# AT91SAM9G20 register map
Vendor: Atmel; File version: 20130207
CPU: 
Registers are 32-bit, read-write, reset 0x0 unless marked. A register's access mark holds for its fields unless they carry their own. Offsets are from the block's base; [hi:lo] are bit positions; 'fields as' and 'values as' point back to an identical list.

## DBGU — Debug Unit
Base 0xFFFFF200; register names take the prefix DBGU_
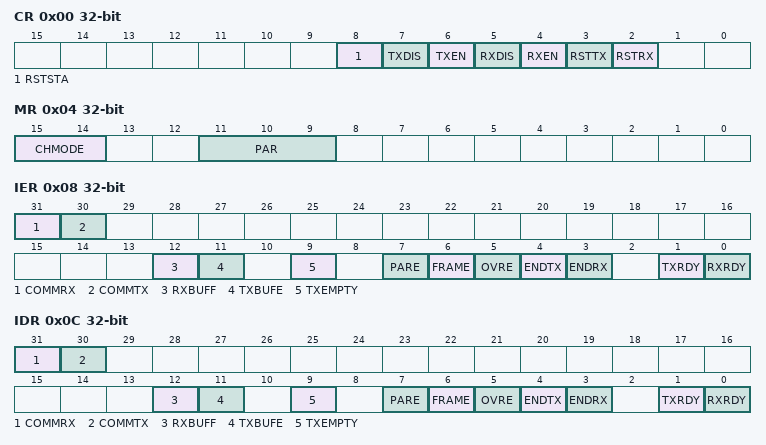
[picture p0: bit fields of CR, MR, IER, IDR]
0x00 CR wo reset not defined — Control Register
  [8] RSTSTA — Reset Status Bits
  [7] TXDIS — Transmitter Disable
  [6] TXEN — Transmitter Enable
  [5] RXDIS — Receiver Disable
  [4] RXEN — Receiver Enable
  [3] RSTTX — Reset Transmitter
  [2] RSTRX — Reset Receiver
0x04 MR — Mode Register
  [15:14] CHMODE — Channel Mode
    0=NORM (Normal Mode); 1=AUTO (Automatic Echo); 2=LOCLOOP (Local Loopback); 3=REMLOOP (Remote Loopback)
  [11:9] PAR — Parity Type
    0=EVEN (Even Parity); 1=ODD (Odd Parity); 2=SPACE (Space: Parity forced to 0); 3=MARK (Mark: Parity forced to 1); 4=NONE (No Parity)
0x08 IER wo reset not defined — Interrupt Enable Register
  [31] COMMRX — Enable COMMRX (from ARM) Interrupt
  [30] COMMTX — Enable COMMTX (from ARM) Interrupt
  [12] RXBUFF — Enable Buffer Full Interrupt
  [11] TXBUFE — Enable Buffer Empty Interrupt
  [9] TXEMPTY — Enable TXEMPTY Interrupt
  [7] PARE — Enable Parity Error Interrupt
  [6] FRAME — Enable Framing Error Interrupt
  [5] OVRE — Enable Overrun Error Interrupt
  [4] ENDTX — Enable End of Transmit Interrupt
  [3] ENDRX — Enable End of Receive Transfer Interrupt
  [1] TXRDY — Enable TXRDY Interrupt
  [0] RXRDY — Enable RXRDY Interrupt
0x0C IDR wo reset not defined — Interrupt Disable Register
  [31] COMMRX — Disable COMMRX (from ARM) Interrupt
  [30] COMMTX — Disable COMMTX (from ARM) Interrupt
  [12] RXBUFF — Disable Buffer Full Interrupt
  [11] TXBUFE — Disable Buffer Empty Interrupt
  [9] TXEMPTY — Disable TXEMPTY Interrupt
  [7] PARE — Disable Parity Error Interrupt
  [6] FRAME — Disable Framing Error Interrupt
  [5] OVRE — Disable Overrun Error Interrupt
  [4] ENDTX — Disable End of Transmit Interrupt
  [3] ENDRX — Disable End of Receive Transfer Interrupt
  [1] TXRDY — Disable TXRDY Interrupt
  [0] RXRDY — Disable RXRDY Interrupt
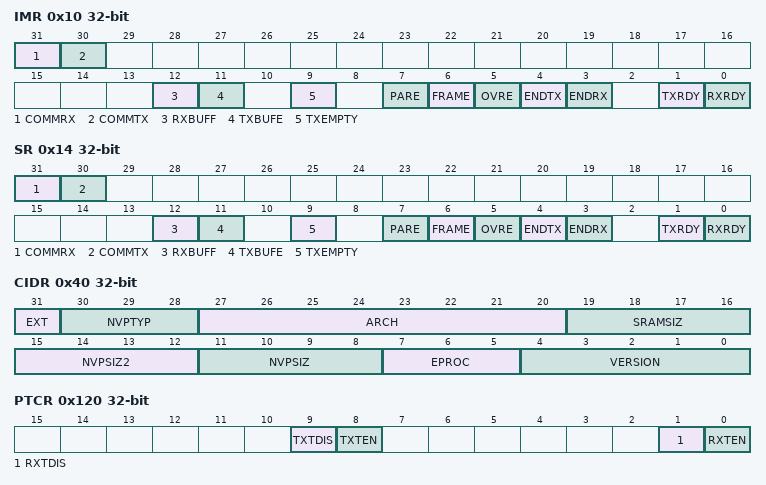
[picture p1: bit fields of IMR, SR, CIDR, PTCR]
0x10 IMR ro — Interrupt Mask Register
  [31] COMMRX — Mask COMMRX Interrupt
  [30] COMMTX — Mask COMMTX Interrupt
  [12] RXBUFF — Mask RXBUFF Interrupt
  [11] TXBUFE — Mask TXBUFE Interrupt
  [9] TXEMPTY — Mask TXEMPTY Interrupt
  [7] PARE — Mask Parity Error Interrupt
  [6] FRAME — Mask Framing Error Interrupt
  [5] OVRE — Mask Overrun Error Interrupt
  [4] ENDTX — Mask End of Transmit Interrupt
  [3] ENDRX — Mask End of Receive Transfer Interrupt
  [1] TXRDY — Disable TXRDY Interrupt
  [0] RXRDY — Mask RXRDY Interrupt
0x14 SR ro reset not defined — Status Register
  [31] COMMRX — Debug Communication Channel Read Status
  [30] COMMTX — Debug Communication Channel Write Status
  [12] RXBUFF — Receive Buffer Full
  [11] TXBUFE — Transmission Buffer Empty
  [9] TXEMPTY — Transmitter Empty
  [7] PARE — Parity Error
  [6] FRAME — Framing Error
  [5] OVRE — Overrun Error
  [4] ENDTX — End of Transmitter Transfer
  [3] ENDRX — End of Receiver Transfer
  [1] TXRDY — Transmitter Ready
  [0] RXRDY — Receiver Ready
0x18 RHR ro — Receive Holding Register
  [7:0] RXCHR — Received Character
0x1C THR wo reset not defined — Transmit Holding Register
  [7:0] TXCHR — Character to be Transmitted
0x20 BRGR — Baud Rate Generator Register
  [15:0] CD — Clock Divisor
    0=DISABLED (DBGU Disabled); 1=MCK
0x40 CIDR ro reset not defined — Chip ID Register
  [31] EXT — Extension Flag
  [30:28] NVPTYP — Nonvolatile Program Memory Type
    0=ROM; 1=ROMLESS (ROMless or on-chip Flash); 2=FLASH (Embedded Flash Memory); 3=ROM_FLASH (ROM and Embedded Flash MemoryNVPSIZ is ROM size NVPSIZ2 is Flash size); 4=SRAM (SRAM emulating ROM)
  [27:20] ARCH — Architecture Identifier
    25=AT91SAM9xx Series; 41=AT91SAM9XExx Series; 52=AT91x34 Series; 55=CAP7 (CAP7 Series); 57=CAP9 (CAP9 Series); 59=CAP11 (CAP11 Series); 64=AT91x40 Series; 66=AT91x42 Series; 85=AT91x55 Series; 96=AT91SAM7Axx Series; 97=AT91SAM7AQxx Series; 99=AT91x63 Series; 112=AT91SAM7Sxx Series; 113=AT91SAM7XCxx Series; 114=AT91SAM7SExx Series; 115=AT91SAM7Lxx Series; 117=AT91SAM7Xxx Series; 118=AT91SAM7SLxx Series; 128=ATSAM3UxC Series (100-pin version); 129=ATSAM3UxE Series (144-pin version); 131=ATSAM3AxC Series (100-pin version); 132=ATSAM3XxC Series (100-pin version); 133=ATSAM3XxE Series (144-pin version); 134=ATSAM3XxG Series (208/217-pin version); 136=ATSAM3SxA Series (48-pin version); 137=ATSAM3SxB Series (64-pin version); 138=ATSAM3SxC Series (100-pin version); 146=AT91x92 Series; 147=ATSAM3NxA Series (48-pin version); 148=ATSAM3NxB Series (64-pin version); 149=ATSAM3NxC Series (100-pin version); 152=ATSAM3SDxA Series (48-pin version); 153=ATSAM3SDxB Series (64-pin version); 154=ATSAM3SDxC Series (100-pin version); 240=AT75Cxx Series
  [19:16] SRAMSIZ — Internal SRAM Size
    1=1K (1K bytes); 2=2K (2K bytes); 3=6K (6K bytes); 4=112K (112K bytes); 5=4K (4K bytes); 6=80K (80K bytes); 7=160K (160K bytes); 8=8K (8K bytes); 9=16K (16K bytes); 10=32K (32K bytes); 11=64K (64K bytes); 12=128K (128K bytes); 13=256K (256K bytes); 14=96K (96K bytes); 15=512K (512K bytes)
  [15:12] NVPSIZ2
    0=NONE; 1=8K (8K bytes); 2=16K (16K bytes); 3=32K (32K bytes); 5=64K (64K bytes); 7=128K (128K bytes); 9=256K (256K bytes); 10=512K (512K bytes); 12=1024K (1024K bytes); 14=2048K (2048K bytes)
  [11:8] NVPSIZ — Nonvolatile Program Memory Size
    values as NVPSIZ2
  [7:5] EPROC — Embedded Processor
    1=ARM946ES; 2=ARM7TDMI; 3=CM3 (Cortex-M3); 4=ARM920T; 5=ARM926EJS; 6=CA5 (Cortex-A5)
  [4:0] VERSION — Version of the Device
0x44 EXID ro reset not defined — Chip ID Extension Register
  [31:0] EXID — Chip ID Extension
0x48 FNR — Force NTRST Register
  [0] FNTRST — Force NTRST
0x100 RPR — Receive Pointer Register
  [31:0] RXPTR
0x104 RCR — Receive Counter Register
  [15:0] RXCTR
0x108 TPR — Transmit Pointer Register
  [31:0] TXPTR — Transmit Counter Register
0x10C TCR — Transmit Counter Register
  [15:0] TXCTR
0x110 RNPR — Receive Next Pointer Register
  [31:0] RXNPTR — Receive Next Pointer
0x114 RNCR — Receive Next Counter Register
  [15:0] RXNCTR — Receive Next Counter
0x118 TNPR — Transmit Next Pointer Register
  [31:0] TXNPTR — Transmit Next Pointer
0x11C TNCR — Transmit Next Counter Register
  [15:0] TXNCTR — Transmit Counter Next
0x120 PTCR wo — Transfer Control Register
  [9] TXTDIS — Transmitter Transfer Disable
  [8] TXTEN — Transmitter Transfer Enable
  [1] RXTDIS — Receiver Transfer Disable
  [0] RXTEN — Receiver Transfer Enable
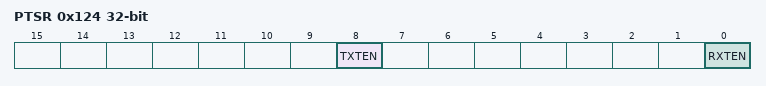
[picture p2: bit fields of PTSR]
0x124 PTSR ro — Transfer Status Register
  [8] TXTEN — Transmitter Transfer Enable
  [0] RXTEN — Receiver Transfer Enable
